AUTOSAR XML (schema 4-2-2)
package /ComponentTypes
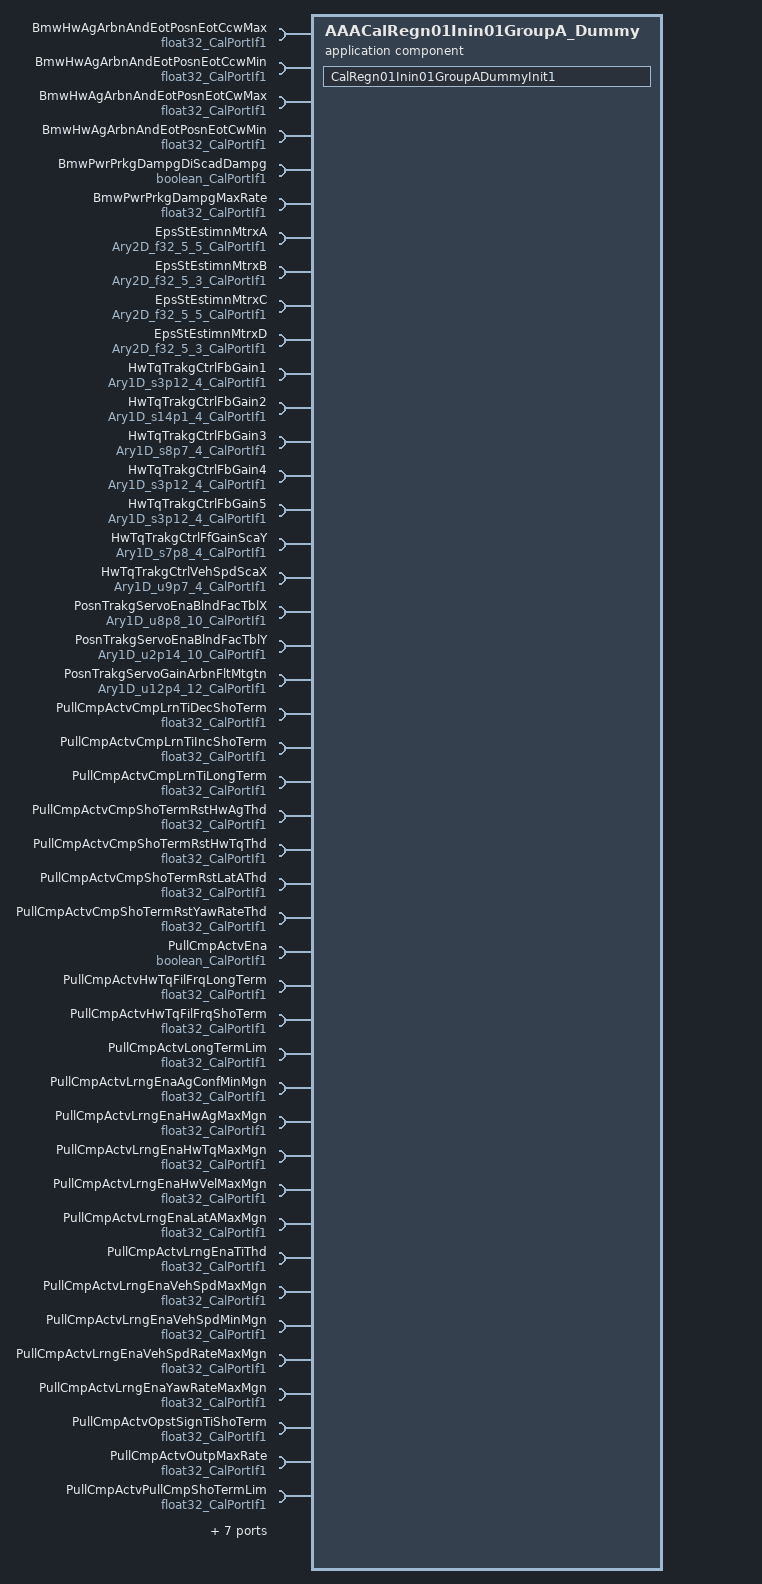
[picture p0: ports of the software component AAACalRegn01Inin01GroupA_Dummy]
  application sw component type AAACalRegn01Inin01GroupA_Dummy
    51 x require port:
      BmwHwAgArbnAndEotPosnEotCcwMax: parameter-require-com-spec{init-value=-360, parameter=Val}, required-interface=float32_CalPortIf1
      BmwHwAgArbnAndEotPosnEotCcwMin: parameter-require-com-spec{init-value=-900, parameter=Val}, required-interface=float32_CalPortIf1
      BmwHwAgArbnAndEotPosnEotCwMax: parameter-require-com-spec{init-value=900, parameter=Val}, required-interface=float32_CalPortIf1
      BmwHwAgArbnAndEotPosnEotCwMin: parameter-require-com-spec{init-value=360, parameter=Val}, required-interface=float32_CalPortIf1
      BmwPwrPrkgDampgDiScadDampg: parameter-require-com-spec{init-value=1, parameter=Logl}, required-interface=boolean_CalPortIf1
      BmwPwrPrkgDampgMaxRate: parameter-require-com-spec{init-value=1, parameter=Val}, required-interface=float32_CalPortIf1
      EpsStEstimnMtrxA: parameter-require-com-spec{init-value=[[1, 0, 0, 0, 0], [0, 1, 0, 0, 0], [0, 0, 1, 0, 0], [0, 0, 0, 1, 0], [0, 0, 0, 0, 1]], parameter=Ary2D}, required-interface=Ary2D_f32_5_5_CalPortIf1
      EpsStEstimnMtrxB: parameter-require-com-spec{init-value=5 x [0, 0, 0], parameter=Ary2D}, required-interface=Ary2D_f32_5_3_CalPortIf1
      EpsStEstimnMtrxC: parameter-require-com-spec{init-value=[[1, 0, 0, 0, 0], [0, 1, 0, 0, 0], [0, 0, 1, 0, 0], [0, 0, 0, 1, 0], [0, 0, 0, 0, 1]], parameter=Ary2D}, required-interface=Ary2D_f32_5_5_CalPortIf1
      EpsStEstimnMtrxD: parameter-require-com-spec{init-value=5 x [0, 0, 0], parameter=Ary2D}, required-interface=Ary2D_f32_5_3_CalPortIf1
      HwTqTrakgCtrlFbGain1: parameter-require-com-spec{init-value=[0, 0, 0, 0], parameter=Ary1D}, required-interface=Ary1D_s3p12_4_CalPortIf1
      HwTqTrakgCtrlFbGain2: parameter-require-com-spec{init-value=[0, 0, 0, 0], parameter=Ary1D}, required-interface=Ary1D_s14p1_4_CalPortIf1
      HwTqTrakgCtrlFbGain3: parameter-require-com-spec{init-value=[0, 0, 0, 0], parameter=Ary1D}, required-interface=Ary1D_s8p7_4_CalPortIf1
      HwTqTrakgCtrlFbGain4: parameter-require-com-spec{init-value=[0, 0, 0, 0], parameter=Ary1D}, required-interface=Ary1D_s3p12_4_CalPortIf1
      HwTqTrakgCtrlFbGain5: parameter-require-com-spec{init-value=[0, 0, 0, 0], parameter=Ary1D}, required-interface=Ary1D_s3p12_4_CalPortIf1
      HwTqTrakgCtrlFfGainScaY: parameter-require-com-spec{init-value=[0, 0, 0, 0], parameter=Ary1D}, required-interface=Ary1D_s7p8_4_CalPortIf1
      HwTqTrakgCtrlVehSpdScaX: parameter-require-com-spec{init-value=[0, 1280, 2560, 25600], parameter=Ary1D}, required-interface=Ary1D_u9p7_4_CalPortIf1
      PosnTrakgServoEnaBlndFacTblX: parameter-require-com-spec{init-value=[0, 26, 51, 77, 128, 256, 512, 768, 1024, 2560], parameter=Ary1D}, required-interface=Ary1D_u8p8_10_CalPortIf1
      PosnTrakgServoEnaBlndFacTblY: parameter-require-com-spec{init-value=[0, 164, 328, 819, 1638, 3277, 8192, 11469, 16384, 16384], parameter=Ary1D}, required-interface=Ary1D_u2p14_10_CalPortIf1
      PosnTrakgServoGainArbnFltMtgtn: parameter-require-com-spec{init-value=[960, 960, 800, 640, 480, 320, 320, 160, 160, 160, 160, 160], parameter=Ary1D}, required-interface=Ary1D_u12p4_12_CalPortIf1
      PullCmpActvCmpLrnTiDecShoTerm: parameter-require-com-spec{init-value=45, parameter=Val}, required-interface=float32_CalPortIf1
      PullCmpActvCmpLrnTiIncShoTerm: parameter-require-com-spec{init-value=45, parameter=Val}, required-interface=float32_CalPortIf1
      PullCmpActvCmpLrnTiLongTerm: parameter-require-com-spec{init-value=45, parameter=Val}, required-interface=float32_CalPortIf1
      PullCmpActvCmpShoTermRstHwAgThd: parameter-require-com-spec{init-value=45, parameter=Val}, required-interface=float32_CalPortIf1
      PullCmpActvCmpShoTermRstHwTqThd: parameter-require-com-spec{init-value=3, parameter=Val}, required-interface=float32_CalPortIf1
      PullCmpActvCmpShoTermRstLatAThd: parameter-require-com-spec{init-value=1, parameter=Val}, required-interface=float32_CalPortIf1
      PullCmpActvCmpShoTermRstYawRateThd: parameter-require-com-spec{init-value=1, parameter=Val}, required-interface=float32_CalPortIf1
      PullCmpActvEna: parameter-require-com-spec{init-value=1, parameter=Logl}, required-interface=boolean_CalPortIf1
      PullCmpActvHwTqFilFrqLongTerm: parameter-require-com-spec{init-value=0.5, parameter=Val}, required-interface=float32_CalPortIf1
      PullCmpActvHwTqFilFrqShoTerm: parameter-require-com-spec{init-value=0.5, parameter=Val}, required-interface=float32_CalPortIf1
      PullCmpActvLongTermLim: parameter-require-com-spec{init-value=0.5, parameter=Val}, required-interface=float32_CalPortIf1
      PullCmpActvLrngEnaAgConfMinMgn: parameter-require-com-spec{init-value=1, parameter=Val}, required-interface=float32_CalPortIf1
      PullCmpActvLrngEnaHwAgMaxMgn: parameter-require-com-spec{init-value=45, parameter=Val}, required-interface=float32_CalPortIf1
      PullCmpActvLrngEnaHwTqMaxMgn: parameter-require-com-spec{init-value=2.8, parameter=Val}, required-interface=float32_CalPortIf1
      PullCmpActvLrngEnaHwVelMaxMgn: parameter-require-com-spec{init-value=10, parameter=Val}, required-interface=float32_CalPortIf1
      PullCmpActvLrngEnaLatAMaxMgn: parameter-require-com-spec{init-value=0.5, parameter=Val}, required-interface=float32_CalPortIf1
      PullCmpActvLrngEnaTiThd: parameter-require-com-spec{init-value=2, parameter=Val}, required-interface=float32_CalPortIf1
      PullCmpActvLrngEnaVehSpdMaxMgn: parameter-require-com-spec{init-value=160, parameter=Val}, required-interface=float32_CalPortIf1
      PullCmpActvLrngEnaVehSpdMinMgn: parameter-require-com-spec{init-value=60, parameter=Val}, required-interface=float32_CalPortIf1
      PullCmpActvLrngEnaVehSpdRateMaxMgn: parameter-require-com-spec{init-value=1, parameter=Val}, required-interface=float32_CalPortIf1
      PullCmpActvLrngEnaYawRateMaxMgn: parameter-require-com-spec{init-value=1, parameter=Val}, required-interface=float32_CalPortIf1
      PullCmpActvOpstSignTiShoTerm: parameter-require-com-spec{init-value=0.1, parameter=Val}, required-interface=float32_CalPortIf1
      PullCmpActvOutpMaxRate: parameter-require-com-spec{init-value=100, parameter=Val}, required-interface=float32_CalPortIf1
      PullCmpActvPullCmpShoTermLim: parameter-require-com-spec{init-value=1, parameter=Val}, required-interface=float32_CalPortIf1
      PullCmpActvPullCmpTotLim: parameter-require-com-spec{init-value=0, parameter=Val}, required-interface=float32_CalPortIf1
      PullCmpActvPullErrLimLongTerm: parameter-require-com-spec{init-value=3, parameter=Val}, required-interface=float32_CalPortIf1
      PullCmpActvPullErrMgnThd: parameter-require-com-spec{init-value=0.25, parameter=Val}, required-interface=float32_CalPortIf1
      PullCmpActvPullErrShoTermLim: parameter-require-com-spec{init-value=3, parameter=Val}, required-interface=float32_CalPortIf1
      PullCmpActvShoTermRampTi: parameter-require-com-spec{init-value=1, parameter=Val}, required-interface=float32_CalPortIf1
      PullCmpActvVehSpdScaTblX: parameter-require-com-spec{init-value=[0, 3840, 7680, 11520], parameter=Ary1D}, required-interface=Ary1D_u9p7_4_CalPortIf1
      PullCmpActvVehSpdScaTblY: parameter-require-com-spec{init-value=[0, 4096, 16384, 16384], parameter=Ary1D}, required-interface=Ary1D_u2p14_4_CalPortIf1
    behavior AAACalRegn01Inin01GroupA_Dummy_InternalBehavior: supports-multiple-instantiation=true
      init event AAACalRegn01Inin01GroupA_Dummy_InitEvent: start-on-event=CalRegn01Inin01GroupADummyInit1
      runnable CalRegn01Inin01GroupADummyInit1
  swc implementation AAACalRegn01Inin00GroupA_Dummy_Implementation: behavior=AAACalRegn01Inin01GroupA_Dummy_InternalBehavior
    code-descriptors:
      code Default: artifact-descriptors=autosar-engineering-object={short-label=Default, category=SWSRC}
